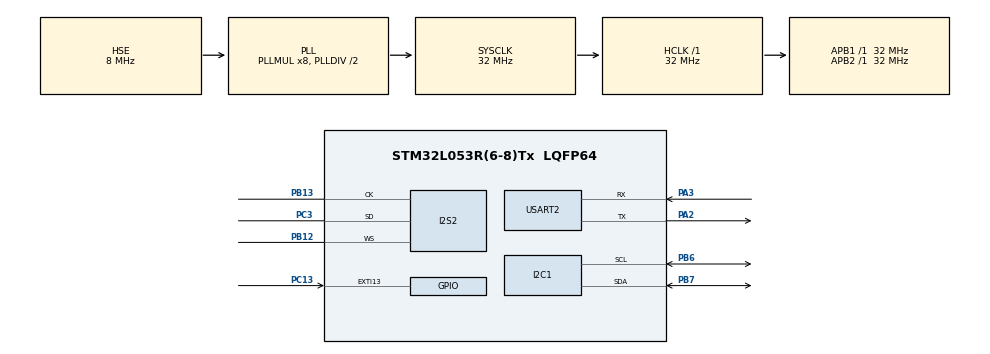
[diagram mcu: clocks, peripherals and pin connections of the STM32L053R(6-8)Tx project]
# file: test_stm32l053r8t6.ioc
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I2C1.Timing=0x00B07CB4
I2S2.ErrorAudioFreq=0.0 %
I2S2.Instance=SPI$Index
I2S2.RealAudioFreq=8.0 KHz
I2S2.VirtualMode=I2S_MODE_MASTER
Mcu.Family=STM32L0
Mcu.Name=STM32L053R(6-8)Tx
Mcu.Package=LQFP64
NVIC.EXTI4_15_IRQn=true\:0\:0\:false\:false\:true\:true\:true\:true
PA13.Mode=Serial_Wire
PA13.Signal=SYS_SWDIO
PA14.Mode=Serial_Wire
PA14.Signal=SYS_SWCLK
PA2.Mode=Asynchronous
PA2.Signal=USART2_TX
PA3.Mode=Asynchronous
PA3.Signal=USART2_RX
PB12.Mode=Half_Duplex_Master
PB12.Signal=I2S2_WS
PB13.Mode=Half_Duplex_Master
PB13.Signal=I2S2_CK
PB6.Mode=I2C
PB6.Signal=I2C1_SCL
PB7.Mode=I2C
PB7.Signal=I2C1_SDA
PC13.Signal=GPXTI13
PC3.Mode=Half_Duplex_Master
PC3.Signal=I2S2_SD
PH0-OSC_IN.Mode=HSE-External-Oscillator
PH0-OSC_IN.Signal=RCC_OSC_IN
PH1-OSC_OUT.Mode=HSE-External-Oscillator
PH1-OSC_OUT.Signal=RCC_OSC_OUT
ProjectManager.HeapSize=0x200
ProjectManager.StackSize=0x400
ProjectManager.TargetToolchain=STM32CubeIDE
RCC.AHBFreq_Value=32000000
RCC.APB1Freq_Value=32000000
RCC.APB1TimFreq_Value=32000000
RCC.APB2Freq_Value=32000000
RCC.APB2TimFreq_Value=32000000
RCC.HCLKFreq_Value=32000000
RCC.HSE_VALUE=8000000
RCC.HSI16_VALUE=16000000
RCC.HSI48_VALUE=48000000
RCC.HSI_VALUE=16000000
RCC.LSE_VALUE=32768
RCC.MSI_VALUE=2097000
RCC.PLLMUL=RCC_PLLMUL_8
RCC.PLLSourceVirtual=RCC_PLLSOURCE_HSE
RCC.SYSCLKFreq_VALUE=32000000
RCC.SYSCLKSource=RCC_SYSCLKSOURCE_PLLCLK
RCC.VCOOutputFreq_Value=64000000
USART2.VirtualMode-Asynchronous=VM_ASYNC
board=custom

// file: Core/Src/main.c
/* USER CODE BEGIN Header */
/**
 ******************************************************************************
 * @file           : main.c
 * @brief          : Main program body
 ******************************************************************************
 * @attention
 *
 * Copyright (c) 2025 STMicroelectronics.
 * All rights reserved.
 *
 * This software is licensed under terms that can be found in the LICENSE file
 * in the root directory of this software component.
 * If no LICENSE file comes with this software, it is provided AS-IS.
 *
 ******************************************************************************
 */
/* USER CODE END Header */
#include "main.h"
#include "i2c.h"
#include "i2s.h"
#include "usart.h"
#include "gpio.h"

/* USER CODE BEGIN PV */
uint8_t stopmode_active = 0;
uint8_t flag_stop = 0;
uint32_t count = 0;
/* USER CODE END PV */

void SystemClock_Config(void);

/* USER CODE BEGIN 0 */
void HAL_GPIO_EXTI_Callback(uint16_t GPIO_Pin) {
  if (GPIO_Pin == GPIO_PIN_13) {
    SystemClock_Config();
    HAL_ResumeTick();
    HAL_UART_Transmit(&huart2, (uint8_t *)"Woke up from Stop Mode\n", 24, HAL_MAX_DELAY);
  }
}
/* USER CODE END 0 */

int main(void)
{

  /* MCU Configuration--------------------------------------------------------*/

  /* Reset of all peripherals, Initializes the Flash interface and the Systick. */
  HAL_Init();

  /* Configure the system clock */
  SystemClock_Config();

  /* Initialize all configured peripherals */
  MX_GPIO_Init();
  MX_I2S2_Init();
  MX_USART2_UART_Init();
  MX_I2C1_Init();
  /* USER CODE BEGIN 2 */
  // GPIO_PinState prev_status = GPIO_PIN_RESET;
  HAL_UART_Transmit(&huart2, (uint8_t *)"Entering Stop Mode\n", 20, HAL_MAX_DELAY);

  HAL_SuspendTick();
  HAL_PWR_EnterSTOPMode(PWR_LOWPOWERREGULATOR_ON, PWR_STOPENTRY_WFI);

  /* USER CODE END 2 */

  /* Infinite loop */
  while (1) {

    /* USER CODE BEGIN 3 */
    HAL_UART_Transmit(&huart2, (uint8_t *)"Entering Stop Mode\n", 20, HAL_MAX_DELAY);
    HAL_SuspendTick();
    HAL_PWR_EnterSTOPMode(PWR_LOWPOWERREGULATOR_ON, PWR_STOPENTRY_WFI);

    // GPIO_PinState current_status = HAL_GPIO_ReadPin(USER_BTN_GPIO_Port, USER_BTN_Pin);
    // if (current_status != prev_status) {
    //   if (current_status == GPIO_PIN_SET) {
    //     // Button pressed - add your code here
    //     // count_press++;
    //     HAL_UART_Transmit(&huart1, (uint8_t *)"Button Pressed\n", 16, HAL_MAX_DELAY);
    //   } else {
    //     // Button released - add your code here
    //     // count_release++;
    //     HAL_UART_Transmit(&huart1, (uint8_t *)"Button Released\n", 17, HAL_MAX_DELAY);
    //   }
    //   prev_status = current_status;
    // }
    // HAL_Delay(10);
    // HAL_UART_Transmit(&huart1, (uint8_t *)"Looping\n", 8, HAL_MAX_DELAY);
    // char test[] = "Looping\n";
    // HAL_UART_Transmit(&huart2, test, sizeof(test) - 1, HAL_MAX_DELAY);
    // HAL_Delay(1000);
  }
  /* USER CODE END 3 */
}

void SystemClock_Config(void)
{
  RCC_OscInitTypeDef RCC_OscInitStruct = {0};
  RCC_ClkInitTypeDef RCC_ClkInitStruct = {0};
  RCC_PeriphCLKInitTypeDef PeriphClkInit = {0};

  /** Configure the main internal regulator output voltage
  */
  __HAL_PWR_VOLTAGESCALING_CONFIG(PWR_REGULATOR_VOLTAGE_SCALE1);

  /** Initializes the RCC Oscillators according to the specified parameters
  * in the RCC_OscInitTypeDef structure.
  */
  RCC_OscInitStruct.OscillatorType = RCC_OSCILLATORTYPE_HSE;
  RCC_OscInitStruct.HSEState = RCC_HSE_ON;
  RCC_OscInitStruct.PLL.PLLState = RCC_PLL_ON;
  RCC_OscInitStruct.PLL.PLLSource = RCC_PLLSOURCE_HSE;
  RCC_OscInitStruct.PLL.PLLMUL = RCC_PLLMUL_8;
  RCC_OscInitStruct.PLL.PLLDIV = RCC_PLLDIV_2;
  if (HAL_RCC_OscConfig(&RCC_OscInitStruct) != HAL_OK)
  {
    Error_Handler();
  }

  /** Initializes the CPU, AHB and APB buses clocks
  */
  RCC_ClkInitStruct.ClockType = RCC_CLOCKTYPE_HCLK|RCC_CLOCKTYPE_SYSCLK
                              |RCC_CLOCKTYPE_PCLK1|RCC_CLOCKTYPE_PCLK2;
  RCC_ClkInitStruct.SYSCLKSource = RCC_SYSCLKSOURCE_PLLCLK;
  RCC_ClkInitStruct.AHBCLKDivider = RCC_SYSCLK_DIV1;
  RCC_ClkInitStruct.APB1CLKDivider = RCC_HCLK_DIV1;
  RCC_ClkInitStruct.APB2CLKDivider = RCC_HCLK_DIV1;

  if (HAL_RCC_ClockConfig(&RCC_ClkInitStruct, FLASH_LATENCY_1) != HAL_OK)
  {
    Error_Handler();
  }
  PeriphClkInit.PeriphClockSelection = RCC_PERIPHCLK_USART2|RCC_PERIPHCLK_I2C1;
  PeriphClkInit.Usart2ClockSelection = RCC_USART2CLKSOURCE_PCLK1;
  PeriphClkInit.I2c1ClockSelection = RCC_I2C1CLKSOURCE_PCLK1;
  if (HAL_RCCEx_PeriphCLKConfig(&PeriphClkInit) != HAL_OK)
  {
    Error_Handler();
  }
}

void Error_Handler(void)
{
  __disable_irq();
  while (1) {
  }
}
